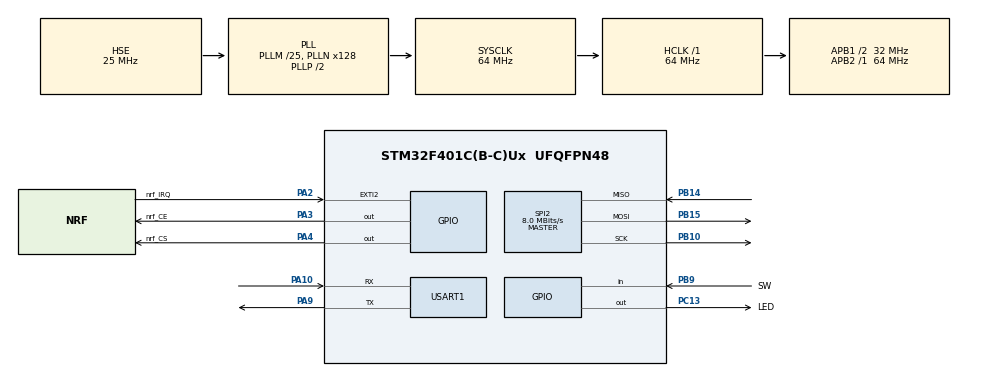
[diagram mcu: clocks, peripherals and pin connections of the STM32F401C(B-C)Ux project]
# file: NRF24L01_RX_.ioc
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FREERTOS.BinarySemaphores01=semFromNrfIRQ_Pin,Dynamic,NULL
FREERTOS.Tasks01=defaultTask,24,128,StartDefaultTask,Default,NULL,Dynamic,NULL,NULL
FREERTOS.configUSE_NEWLIB_REENTRANT=1
Mcu.Family=STM32F4
Mcu.Name=STM32F401C(B-C)Ux
Mcu.Package=UFQFPN48
NVIC.EXTI2_IRQn=true\:5\:0\:true\:false\:true\:false\:true\:true\:true
NVIC.PriorityGroup=NVIC_PRIORITYGROUP_4
NVIC.TIM1_UP_TIM10_IRQn=true\:15\:0\:false\:false\:true\:false\:false\:true\:true
NVIC.TimeBase=TIM1_UP_TIM10_IRQn
NVIC.TimeBaseIP=TIM10
PA10.Mode=Asynchronous
PA10.Signal=USART1_RX
PA13.Mode=Serial_Wire
PA13.Signal=SYS_JTMS-SWDIO
PA14.Mode=Serial_Wire
PA14.Signal=SYS_JTCK-SWCLK
PA2.GPIO_Label=nrf_IRQ
PA2.Signal=GPXTI2
PA3.GPIO_Label=nrf_CE
PA3.Signal=GPIO_Output
PA4.GPIO_Label=nrf_CS
PA4.GPIO_Speed=GPIO_SPEED_FREQ_LOW
PA4.Signal=GPIO_Output
PA9.Mode=Asynchronous
PA9.Signal=USART1_TX
PB10.Mode=Full_Duplex_Master
PB10.Signal=SPI2_SCK
PB14.Mode=Full_Duplex_Master
PB14.Signal=SPI2_MISO
PB15.Mode=Full_Duplex_Master
PB15.Signal=SPI2_MOSI
PB9.GPIO_Label=SW
PB9.Signal=GPIO_Input
PC13-ANTI_TAMP.GPIO_Label=LED
PC13-ANTI_TAMP.Signal=GPIO_Output
PC14-OSC32_IN.Mode=LSE-External-Oscillator
PC14-OSC32_IN.Signal=RCC_OSC32_IN
PC15-OSC32_OUT.Mode=LSE-External-Oscillator
PC15-OSC32_OUT.Signal=RCC_OSC32_OUT
PH0\ -\ OSC_IN.Mode=HSE-External-Oscillator
PH0\ -\ OSC_IN.Signal=RCC_OSC_IN
PH1\ -\ OSC_OUT.Mode=HSE-External-Oscillator
PH1\ -\ OSC_OUT.Signal=RCC_OSC_OUT
ProjectManager.HeapSize=0x200
ProjectManager.StackSize=0x400
ProjectManager.TargetToolchain=STM32CubeIDE
RCC.48MHZClocksFreq_Value=32000000
RCC.AHBFreq_Value=64000000
RCC.APB1CLKDivider=RCC_HCLK_DIV2
RCC.APB1Freq_Value=32000000
RCC.APB1TimFreq_Value=64000000
RCC.APB2Freq_Value=64000000
RCC.APB2TimFreq_Value=64000000
RCC.CortexFreq_Value=64000000
RCC.HCLKFreq_Value=64000000
RCC.HSE_VALUE=25000000
RCC.HSI_VALUE=16000000
RCC.PLLM=25
RCC.PLLN=128
RCC.PLLSourceVirtual=RCC_PLLSOURCE_HSE
RCC.SYSCLKFreq_VALUE=64000000
RCC.SYSCLKSource=RCC_SYSCLKSOURCE_PLLCLK
RCC.VCOOutputFreq_Value=128000000
SPI2.BaudRatePrescaler=SPI_BAUDRATEPRESCALER_4
SPI2.CalculateBaudRate=8.0 MBits/s
SPI2.Direction=SPI_DIRECTION_2LINES
SPI2.Mode=SPI_MODE_MASTER
SPI2.VirtualType=VM_MASTER
USART1.VirtualMode=VM_ASYNC
VP_FREERTOS_VS_CMSIS_V2.Mode=CMSIS_V2
VP_SYS_VS_tim10.Mode=TIM10
board=custom

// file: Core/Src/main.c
/* USER CODE BEGIN Header */
/**
  ******************************************************************************
  * @file           : main.c
  * @brief          : Main program body
  ******************************************************************************
  * @attention
  *
  * Copyright (c) 2023 STMicroelectronics.
  * All rights reserved.
  *
  * This software is licensed under terms that can be found in the LICENSE file
  * in the root directory of this software component.
  * If no LICENSE file comes with this software, it is provided AS-IS.
  *
  ******************************************************************************
  */
/* USER CODE END Header */
#include "main.h"
#include "cmsis_os.h"

/* USER CODE BEGIN Includes */
#include <string.h>
#include "semphr.h"
#include "stdbool.h"

#include "nrf24L01/nrf24L01.h"

char str1[40] = {0};
uint8_t buf1[40] = {0};

/* USER CODE END Includes */

SPI_HandleTypeDef hspi2;

UART_HandleTypeDef huart1;

/* Definitions for defaultTask */
osThreadId_t defaultTaskHandle;
const osThreadAttr_t defaultTask_attributes = {
  .name = "defaultTask",
  .stack_size = 128 * 4,
  .priority = (osPriority_t) osPriorityNormal,
};
/* Definitions for semFromNrfIRQ_Pin */
osSemaphoreId_t semFromNrfIRQ_PinHandle;
const osSemaphoreAttr_t semFromNrfIRQ_Pin_attributes = {
  .name = "semFromNrfIRQ_Pin"
};

void SystemClock_Config(void);
static void MX_GPIO_Init(void);
static void MX_SPI2_Init(void);
static void MX_USART1_UART_Init(void);
void StartDefaultTask(void *argument);

/* USER CODE BEGIN PFP */
void PWM_Tim_Init(uint8_t ServoNum, uint32_t DutyCycle);
void Set_Servo_Angle(uint8_t ServoNum, uint8_t angle);
void Test_Servo_Motor(void);
/* USER CODE END PFP */

int main(void)
{

  /* MCU Configuration--------------------------------------------------------*/

  /* Reset of all peripherals, Initializes the Flash interface and the Systick. */
  HAL_Init();

  /* Configure the system clock */
  SystemClock_Config();

  /* Initialize all configured peripherals */
  MX_GPIO_Init();
  MX_SPI2_Init();
  MX_USART1_UART_Init();
  /* USER CODE BEGIN 2 */

 // testReadWriteSetingd();			// For debug

  /* USER CODE END 2 */

  /* Init scheduler */
  osKernelInitialize();

  /* Create the semaphores(s) */
  /* creation of semFromNrfIRQ_Pin */
  semFromNrfIRQ_PinHandle = osSemaphoreNew(1, 1, &semFromNrfIRQ_Pin_attributes);

  /* Create the thread(s) */
  /* creation of defaultTask */
  defaultTaskHandle = osThreadNew(StartDefaultTask, NULL, &defaultTask_attributes);

  /* Start scheduler */
  osKernelStart();

  /* We should never get here as control is now taken by the scheduler */
  /* Infinite loop */
  while (1)
  {

  }
}

void SystemClock_Config(void)
{
  RCC_OscInitTypeDef RCC_OscInitStruct = {0};
  RCC_ClkInitTypeDef RCC_ClkInitStruct = {0};

  /** Configure the main internal regulator output voltage
  */
  __HAL_RCC_PWR_CLK_ENABLE();
  __HAL_PWR_VOLTAGESCALING_CONFIG(PWR_REGULATOR_VOLTAGE_SCALE2);

  /** Initializes the RCC Oscillators according to the specified parameters
  * in the RCC_OscInitTypeDef structure.
  */
  RCC_OscInitStruct.OscillatorType = RCC_OSCILLATORTYPE_HSE;
  RCC_OscInitStruct.HSEState = RCC_HSE_ON;
  RCC_OscInitStruct.PLL.PLLState = RCC_PLL_ON;
  RCC_OscInitStruct.PLL.PLLSource = RCC_PLLSOURCE_HSE;
  RCC_OscInitStruct.PLL.PLLM = 25;
  RCC_OscInitStruct.PLL.PLLN = 128;
  RCC_OscInitStruct.PLL.PLLP = RCC_PLLP_DIV2;
  RCC_OscInitStruct.PLL.PLLQ = 4;
  if (HAL_RCC_OscConfig(&RCC_OscInitStruct) != HAL_OK)
  {
    Error_Handler();
  }

  /** Initializes the CPU, AHB and APB buses clocks
  */
  RCC_ClkInitStruct.ClockType = RCC_CLOCKTYPE_HCLK|RCC_CLOCKTYPE_SYSCLK
                              |RCC_CLOCKTYPE_PCLK1|RCC_CLOCKTYPE_PCLK2;
  RCC_ClkInitStruct.SYSCLKSource = RCC_SYSCLKSOURCE_PLLCLK;
  RCC_ClkInitStruct.AHBCLKDivider = RCC_SYSCLK_DIV1;
  RCC_ClkInitStruct.APB1CLKDivider = RCC_HCLK_DIV2;
  RCC_ClkInitStruct.APB2CLKDivider = RCC_HCLK_DIV1;

  if (HAL_RCC_ClockConfig(&RCC_ClkInitStruct, FLASH_LATENCY_2) != HAL_OK)
  {
    Error_Handler();
  }
}

static void MX_SPI2_Init(void)
{

  /* SPI2 parameter configuration*/
  hspi2.Instance = SPI2;
  hspi2.Init.Mode = SPI_MODE_MASTER;
  hspi2.Init.Direction = SPI_DIRECTION_2LINES;
  hspi2.Init.DataSize = SPI_DATASIZE_8BIT;
  hspi2.Init.CLKPolarity = SPI_POLARITY_LOW;
  hspi2.Init.CLKPhase = SPI_PHASE_1EDGE;
  hspi2.Init.NSS = SPI_NSS_SOFT;
  hspi2.Init.BaudRatePrescaler = SPI_BAUDRATEPRESCALER_4;
  hspi2.Init.FirstBit = SPI_FIRSTBIT_MSB;
  hspi2.Init.TIMode = SPI_TIMODE_DISABLE;
  hspi2.Init.CRCCalculation = SPI_CRCCALCULATION_DISABLE;
  hspi2.Init.CRCPolynomial = 10;
  if (HAL_SPI_Init(&hspi2) != HAL_OK)
  {
    Error_Handler();
  }

}

static void MX_USART1_UART_Init(void)
{

  huart1.Instance = USART1;
  huart1.Init.BaudRate = 115200;
  huart1.Init.WordLength = UART_WORDLENGTH_8B;
  huart1.Init.StopBits = UART_STOPBITS_1;
  huart1.Init.Parity = UART_PARITY_NONE;
  huart1.Init.Mode = UART_MODE_TX_RX;
  huart1.Init.HwFlowCtl = UART_HWCONTROL_NONE;
  huart1.Init.OverSampling = UART_OVERSAMPLING_16;
  if (HAL_UART_Init(&huart1) != HAL_OK)
  {
    Error_Handler();
  }

}

static void MX_GPIO_Init(void)
{
  GPIO_InitTypeDef GPIO_InitStruct = {0};

  /* GPIO Ports Clock Enable */
  __HAL_RCC_GPIOC_CLK_ENABLE();
  __HAL_RCC_GPIOH_CLK_ENABLE();
  __HAL_RCC_GPIOA_CLK_ENABLE();
  __HAL_RCC_GPIOB_CLK_ENABLE();

  /*Configure GPIO pin Output Level */
  HAL_GPIO_WritePin(LED_GPIO_Port, LED_Pin, GPIO_PIN_RESET);

  /*Configure GPIO pin Output Level */
  HAL_GPIO_WritePin(GPIOA, nrf_CE_Pin|nrf_CS_Pin, GPIO_PIN_RESET);

  /*Configure GPIO pin : LED_Pin */
  GPIO_InitStruct.Pin = LED_Pin;
  GPIO_InitStruct.Mode = GPIO_MODE_OUTPUT_PP;
  GPIO_InitStruct.Pull = GPIO_NOPULL;
  GPIO_InitStruct.Speed = GPIO_SPEED_FREQ_LOW;
  HAL_GPIO_Init(LED_GPIO_Port, &GPIO_InitStruct);

  /*Configure GPIO pin : nrf_IRQ_Pin */
  GPIO_InitStruct.Pin = nrf_IRQ_Pin;
  GPIO_InitStruct.Mode = GPIO_MODE_IT_RISING;
  GPIO_InitStruct.Pull = GPIO_NOPULL;
  HAL_GPIO_Init(nrf_IRQ_GPIO_Port, &GPIO_InitStruct);

  /*Configure GPIO pins : nrf_CE_Pin nrf_CS_Pin */
  GPIO_InitStruct.Pin = nrf_CE_Pin|nrf_CS_Pin;
  GPIO_InitStruct.Mode = GPIO_MODE_OUTPUT_PP;
  GPIO_InitStruct.Pull = GPIO_NOPULL;
  GPIO_InitStruct.Speed = GPIO_SPEED_FREQ_LOW;
  HAL_GPIO_Init(GPIOA, &GPIO_InitStruct);

  /*Configure GPIO pin : SW_Pin */
  GPIO_InitStruct.Pin = SW_Pin;
  GPIO_InitStruct.Mode = GPIO_MODE_INPUT;
  GPIO_InitStruct.Pull = GPIO_NOPULL;
  HAL_GPIO_Init(SW_GPIO_Port, &GPIO_InitStruct);

  /* EXTI interrupt init*/
  HAL_NVIC_SetPriority(EXTI2_IRQn, 5, 0);
  HAL_NVIC_EnableIRQ(EXTI2_IRQn);

}

void StartDefaultTask(void *argument)
{
  /* USER CODE BEGIN 5 */
  /* Infinite loop */
	NRF24_init();

  for(;;)
  {
	  // testReadWriteSetingd();
	  NRF24L01_Receive();
	  osDelay(1);
  }
  /* USER CODE END 5 */
}

void HAL_TIM_PeriodElapsedCallback(TIM_HandleTypeDef *htim)
{
  if (htim->Instance == TIM10) {
    HAL_IncTick();
  }
}

void Error_Handler(void)
{
  __disable_irq();
  while (1)
  {
  }
}
